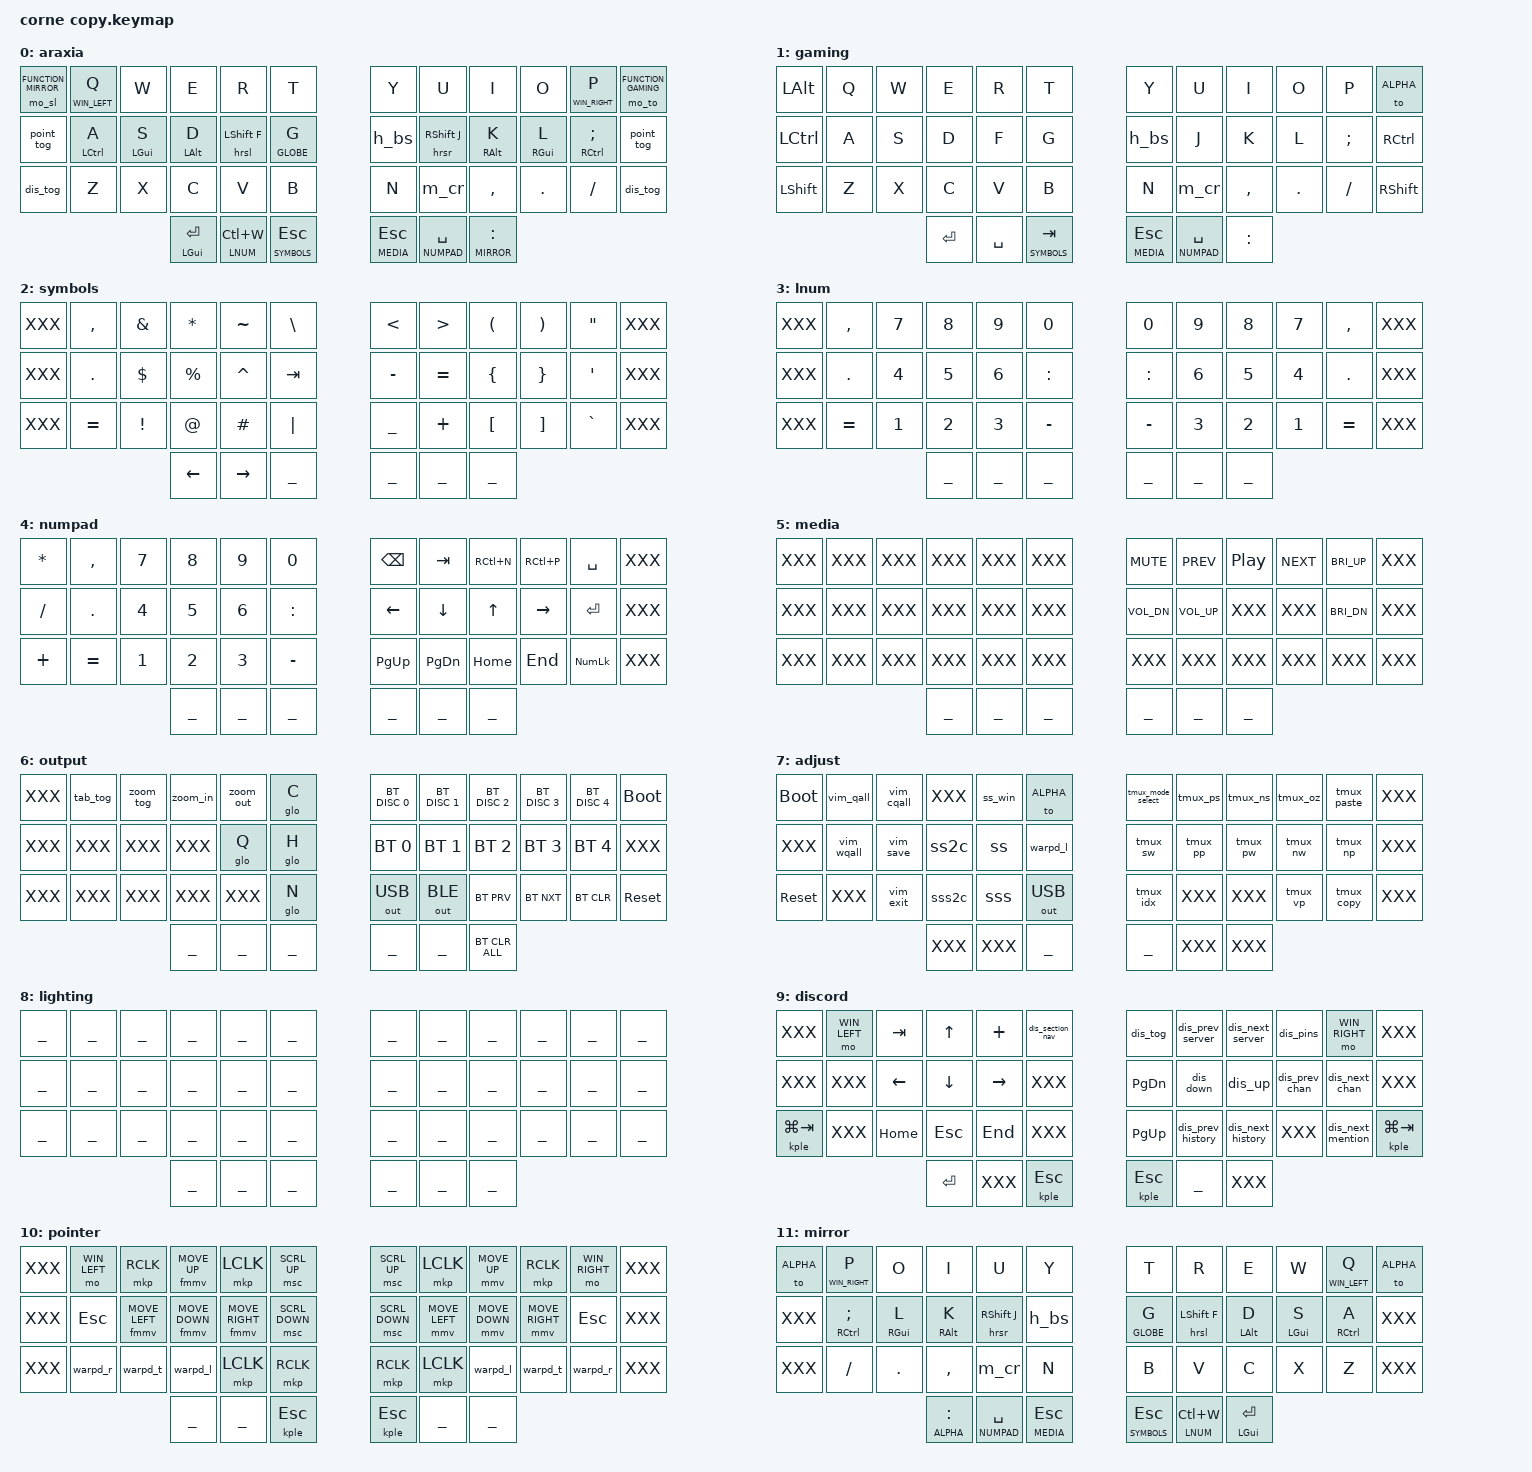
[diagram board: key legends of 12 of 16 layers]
#include "includes/common.dtsi"
#include "includes/settings.dtsi"


#include "zmk-helpers/key-labels/42.h"
#define KEYS_L LT0 LT1 LT2 LT3 LT4 LT5 LM0 LM1 LM2 LM3 LM4 LM5 LB0 LB1 LB2 LB3 LB4 LB5
#define KEYS_R RT0 RT1 RT2 RT3 RT4 RT5 RM0 RM1 RM2 RM3 RM4 RM5 RB0 RB1 RB2 RB3 RB4 RB5
#define THUMBS LH2 LH1 LH0 RH0 RH1 RH2

#include "includes/custom_keycodes.dtsi"
#include "includes/macros.dtsi"
#include "includes/combos.dtsi"
#include "includes/behaviors.dtsi"
#include "includes/conditional_layers.dtsi"


/ {
    keymap {
        compatible = "zmk,keymap";
        /* 0 Layer */
        ALPHA   {
            display-name = "araxia";
            bindings = <
// clang-format off
 &mo_sl FUNCTION MIRROR  &lttp WIN_LEFT Q  &kp W         &kp E              &kp R             &kp T                &kp Y            &kp U               &kp I               &kp O         &lttp WIN_RIGHT P  &mo_to FUNCTION GAMING
 &point_tog              &hrml LCTRL A     &hrml LGUI S  &hrml LALT D       &hrsl LSHIFT F    &hrml GLOBE G        &h_bs            &hrsr RSHIFT J      &hrmr RALT K        &hrmr RGUI L  &hrmr RCTRL SEMI   &point_tog
 &dis_tog                &kp Z             &kp X         &kp C              &kp V             &kp B                &kp N            &m_cr               &kp COMMA           &kp DOT       &kp SLASH          &dis_tog
                                                         &mthp LGUI RETURN  &lthp LNUM LC(W)  &lthp SYMBOLS ESC    &lthp MEDIA ESC  &lttp NUMPAD SPACE  &lthp MIRROR COLON
            >;
        };

        /* 1 Layer */
        gaming {
            display-name = "gaming";
            bindings = <
 &kp LALT    &kp Q  &kp W  &kp E       &kp R      &kp T                &kp Y            &kp U               &kp I      &kp O    &kp P      &to ALPHA
 &kp LCTRL   &kp A  &kp S  &kp D       &kp F      &kp G                &h_bs            &kp J               &kp K      &kp L    &kp SEMI   &kp RCTRL
 &kp LSHIFT  &kp Z  &kp X  &kp C       &kp V      &kp B                &kp N            &m_cr               &kp COMMA  &kp DOT  &kp SLASH  &kp RSHIFT
                           &kp RETURN  &kp SPACE  &lthp SYMBOLS TAB    &lthp MEDIA ESC  &lttp NUMPAD SPACE  &kp COLON
            >;
        };

        /* 2 Layer */
        symbols {
            display-name = "symbols";
            bindings = <
XXX    &kp COMMA  &kp AMPERSAND    &kp ASTERISK  &kp TILDE   &kp BACKSLASH     &kp LESS_THAN   &kp GREATER_THAN  &kp LEFT_PARENTHESIS  &kp RIGHT_PARENTHESIS  &kp DOUBLE_QUOTES  XXX  
XXX    &kp DOT    &kp DOLLAR       &kp PERCENT   &kp CARET   &kp TAB           &kp MINUS       &kp EQUAL         &kp LEFT_BRACE        &kp RIGHT_BRACE        &kp SINGLE_QUOTE   XXX  
XXX    &kp EQUAL  &kp EXCLAMATION  &kp AT        &kp POUND   &kp PIPE          &kp UNDERSCORE  &kp PLUS          &kp LEFT_BRACKET      &kp RIGHT_BRACKET      &kp GRAVE          XXX  
                                   &kp LEFT      &kp RIGHT   ___              ___            ___              ___  
            >;
        };

        /* 3 Layer */
        lnum {
            display-name = "lnum";
            bindings = <
XXX    &kp COMMA  &kp N7  &kp N8  &kp N9  &kp N0        &kp N0     &kp N9  &kp N8  &kp N7  &kp COMMA  XXX  
XXX    &kp DOT    &kp N4  &kp N5  &kp N6  &kp COLON     &kp COLON  &kp N6  &kp N5  &kp N4  &kp DOT    XXX  
XXX    &kp EQUAL  &kp N1  &kp N2  &kp N3  &kp MINUS     &kp MINUS  &kp N3  &kp N2  &kp N1  &kp EQUAL  XXX  
                          ___    ___    ___          ___       ___    ___  
            >;
        };

        /* 4 Layer */
        numpad {
            display-name = "numpad";
            bindings = <
&kp ASTERISK  &kp COMMA  &kp N7  &kp N8  &kp N9  &kp N0        &kp BACKSPACE  &kp TAB        &kp RC(N)  &kp RC(P)  &kp SPACE       XXX  
&kp SLASH     &kp DOT    &kp N4  &kp N5  &kp N6  &kp COLON     &kp LEFT       &kp DOWN       &kp UP     &kp RIGHT  &kp RETURN      XXX  
&kp PLUS      &kp EQUAL  &kp N1  &kp N2  &kp N3  &kp MINUS     &kp PAGE_UP    &kp PAGE_DOWN  &kp HOME   &kp END    &kp KP_NUMLOCK  XXX  
                                 ___    ___    ___          ___           ___           ___  
            >;
        };

        /* 5 Layer */
        media {
            display-name = "media";
            bindings = <
XXX    XXX    XXX    XXX     XXX     XXX       &kp C_MUTE    &kp C_PREV    &kp C_PP      &kp C_NEXT    &kp C_BRI_UP  XXX  
XXX    XXX    XXX    XXX     XXX     XXX       &kp C_VOL_DN  &kp C_VOL_UP  XXX           XXX           &kp C_BRI_DN  XXX  
XXX    XXX    XXX    XXX     XXX     XXX       XXX           XXX           XXX           XXX           XXX           XXX  
                     ___    ___    ___      ___          ___          ___  
            >;
        };

        /* 6 Layer */
        output {
            display-name = "output";
            bindings = <
XXX    &tab_tog  &zoom_tog  &zoom_in  &zoom_out  &glo C     &bt BT_DISC 0 &bt BT_DISC 1 &bt BT_DISC 2 &bt BT_DISC 3   &bt BT_DISC 4  &bootloader
XXX    XXX       XXX        XXX       &glo Q     &glo H     &bt BT_SEL 0  &bt BT_SEL 1  &bt BT_SEL 2  &bt BT_SEL 3    &bt BT_SEL 4   XXX  
XXX    XXX       XXX        XXX       XXX        &glo N     &out OUT_USB  &out OUT_BLE  &bt BT_PRV    &bt BT_NXT      &bt BT_CLR     &sys_reset
                            ___      ___       ___       ___          ___          &bt BT_CLR_ALL
            >;
        };

        /* 7 Layer */
        adjust {
            display-name = "adjust";
            bindings = <
&bootloader  &vim_qall   &vim_cqall  XXX     &ss_win  &to ALPHA      &tmux_mode_select  &tmux_ps  &tmux_ns  &tmux_oz  &tmux_paste  XXX  
XXX          &vim_wqall  &vim_save   &ss2c   &ss      &warpd_l         &tmux_sw           &tmux_pp  &tmux_pw  &tmux_nw  &tmux_np     XXX  
&sys_reset   XXX         &vim_exit   &sss2c  &sss     &out OUT_USB     &tmux_idx          XXX       XXX       &tmux_vp  &tmux_copy   XXX  
                                     XXX     XXX      ___             ___               XXX       XXX  
            >;
        };

        /* 8 Layer */
        /* Do not use this then-layer for regular layer switching */
        lighting {
            display-name = "lighting";
            bindings = <
___    ___    ___    ___    ___    ___    ___    ___    ___    ___    ___    ___
___    ___    ___    ___    ___    ___    ___    ___    ___    ___    ___    ___
___    ___    ___    ___    ___    ___    ___    ___    ___    ___    ___    ___    
                     ___    ___    ___    ___    ___    ___     
            >;
        };

        /* 9 Layer */
        discord {
            display-name = "discord";
            bindings = <
XXX           &mo WIN_LEFT  &kp TAB   &kp UP      &kp PLUS   &dis_section_nav    &dis_tog       &dis_prev_server      &dis_next_server       &dis_pins       &mo WIN_RIGHT      XXX  
XXX           XXX           &kp LEFT  &kp DOWN    &kp RIGHT  XXX                 &kp PAGE_DOWN  &dis_down             &dis_up                &dis_prev_chan  &dis_next_chan     XXX  
&kple LG(TAB) XXX           &kp HOME  &kp ESC     &kp END    XXX                 &kp PAGE_UP    &dis_prev_history     &dis_next_history      XXX             &dis_next_mention  &kple LG(TAB)
                                      &kp RETURN  XXX        &kple ESC           &kple ESC      ___                  XXX  
            >;
        };

        /* 10 Layer */
        pointer {
            display-name = "pointer";
            bindings = <
XXX    &mo WIN_LEFT  &mkp RCLK        &fmmv MOVE_UP    &mkp LCLK         &msc SCRL_UP      &msc SCRL_UP    &mkp LCLK       &mmv MOVE_UP    &mkp RCLK        &mo WIN_RIGHT  XXX  
XXX    &kp ESC       &fmmv MOVE_LEFT  &fmmv MOVE_DOWN  &fmmv MOVE_RIGHT  &msc SCRL_DOWN    &msc SCRL_DOWN  &mmv MOVE_LEFT  &mmv MOVE_DOWN  &mmv MOVE_RIGHT  &kp ESC        XXX  
XXX    &warpd_r      &warpd_t         &warpd_l         &mkp LCLK         &mkp RCLK         &mkp RCLK       &mkp LCLK       &warpd_l        &warpd_t         &warpd_r       XXX  
                                      ___             ___              &kple ESC         &kple ESC       ___            ___  
            >;
        };

        /* 11 Layer */
        mirror {
            display-name = "mirror";
            bindings = <
 &to ALPHA  &lttp WIN_RIGHT P  &kp O         &kp I                &kp U               &kp Y              &kp T              &kp R             &kp E              &kp W         &lttp WIN_LEFT Q  &to ALPHA
 XXX          &hrmr RCTRL SEMI   &hrmr RGUI L  &hrmr RALT K         &hrsr RSHIFT J      &h_bs              &hrml GLOBE G      &hrsl LSHIFT F    &hrml LALT D       &hrml LGUI S  &hrml RCTRL A     XXX  
 XXX          &kp SLASH          &kp DOT       &kp COMMA            &m_cr               &kp N              &kp B              &kp V             &kp C              &kp X         &kp Z             XXX  
                                               &lthp ALPHA COLON  &lthp NUMPAD SPACE  &lthp MEDIA ESC    &lthp SYMBOLS ESC  &lthp LNUM LC(W)  &mthp LGUI RETURN
            >;
        };

        /* 12 Layer */
        window_left {
            display-name = "move [L]";
            bindings = <
XXX    ___         &forward   &backward   &tab_next   &tab_prev    &act Y  &act U  &act I          &act O             &act P         XXX  
XXX    &kp C_SLEEP  &win_quad  &win_third  &win_half   &win_full    &act H  &act J  &act K          &act L             &act COLON     XXX  
XXX    &kp C_POWER  XXX        XXX         &sk LSHIFT  &win_next    &act N  &act M  &act LESS_THAN  &act GREATER_THAN  &act QUESTION  XXX  
                               XXX         XXX         XXX          XXX     XXX     XXX  
            >;
        };

        /* 13 Layer */
        window_right {
            display-name = "move [R]";
            bindings = <
XXX    &act Q  &act W  &act E  &act R  &act T    &tab_prev   &tab_next   &backward   &forward   ___         XXX  
XXX    &act A  &act S  &act D  &act F  &act G    &win_full   &win_half   &win_third  &win_quad  &kp C_SLEEP  XXX  
XXX    &act Z  &act X  &act C  &act V  &act B    &win_next   &sk RSHIFT  XXX         XXX        &kp C_POWER  XXX  
                       XXX     XXX     XXX       XXX         XXX         XXX  
            >;
        };

        /* 14 Layer */
        act {
            display-name = "act";
            bindings = <
XXX    &act Q  &act W  &act E  &act R  &act T     &act Y  &act U  &act I          &act O             &act P         XXX  
XXX    &act A  &act S  &act D  &act F  &act G     &act H  &act J  &act K          &act L             &act COLON     XXX  
XXX    &act Z  &act X  &act C  &act V  &act B     &act N  &act M  &act LESS_THAN  &act GREATER_THAN  &act QUESTION  XXX  
                       ___    ___    ___       ___    ___    ___  
            >;
        };

        /* 15 Layer */
        func {
            display-name = "func";
            bindings = <
XXX    &kp F1  &kp F2   &kp F3   &kp F4   &f2_menu      &help_menu  &kp F13   &kp F14   &kp F15    &kp F16  XXX  
XXX    &kp F5  &kp F6   &kp F7   &kp F8   &f2_status    &point_tog  &kp F17   &kp F18   &kp F19    &kp F20  XXX  
XXX    &kp F9  &kp F10  &kp F11  &kp F12  &f2_dock      &dis_tog    &kp F21   &kp F22   &kp F23    &kp F24  XXX  
                        ___     ___     ___          ___        ___      ___  
            >;
        };

    };

};
// }}}
/* vim: set ft=dts: */
